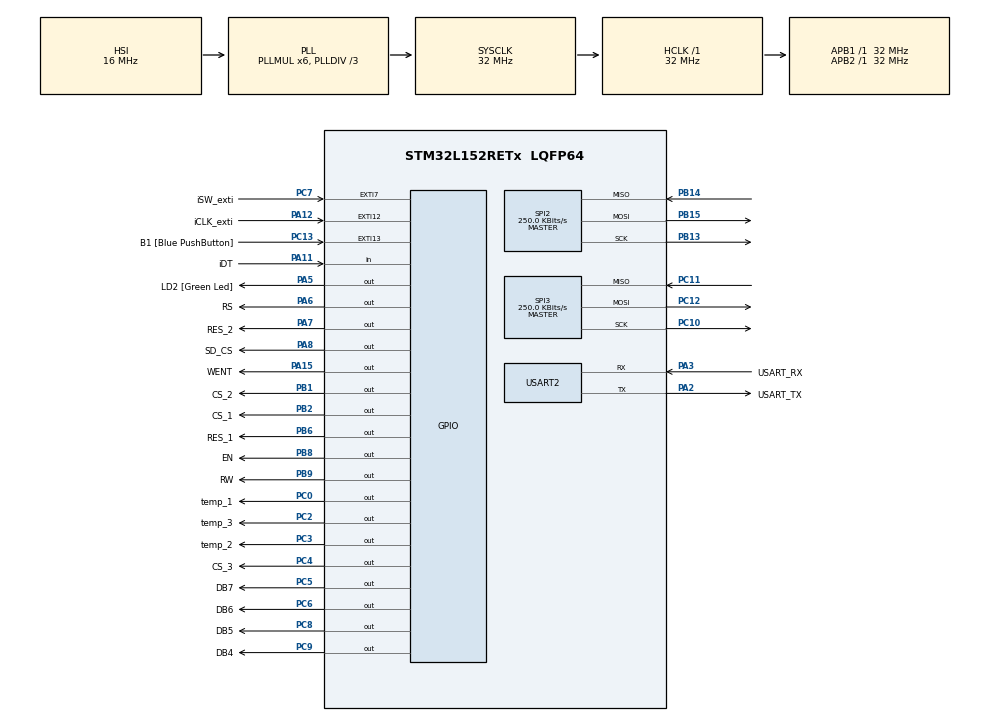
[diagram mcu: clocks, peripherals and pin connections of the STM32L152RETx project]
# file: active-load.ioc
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FATFS._FS_TIMEOUT=100000
Mcu.Family=STM32L1
Mcu.Name=STM32L152RETx
Mcu.Package=LQFP64
NVIC.EXTI15_10_IRQn=true\:0\:0\:false\:false\:true\:true\:true\:true
NVIC.EXTI9_5_IRQn=true\:0\:0\:false\:false\:true\:true\:true\:true
NVIC.PriorityGroup=NVIC_PRIORITYGROUP_0
NVIC.SPI3_IRQn=true\:0\:0\:false\:false\:true\:true\:true\:true
NVIC.TIM2_IRQn=true\:0\:0\:false\:false\:true\:true\:true\:true
NVIC.USART2_IRQn=true\:0\:0\:false\:false\:true\:true\:true\:true
PA11.GPIO_Label=iDT
PA11.GPIO_PuPd=GPIO_PULLDOWN
PA11.Signal=GPIO_Input
PA12.GPIO_Label=iCLK_exti
PA12.GPIO_ModeDefaultEXTI=GPIO_MODE_IT_FALLING
PA12.GPIO_PuPd=GPIO_PULLDOWN
PA12.Signal=GPXTI12
PA13.GPIO_Label=TMS
PA13.Mode=Serial_Wire
PA13.Signal=SYS_JTMS-SWDIO
PA14.GPIO_Label=TCK
PA14.Mode=Serial_Wire
PA14.Signal=SYS_JTCK-SWCLK
PA15.GPIO_Label=WENT
PA15.PinState=GPIO_PIN_SET
PA15.Signal=GPIO_Output
PA2.GPIO_Label=USART_TX
PA2.Mode=Asynchronous
PA2.Signal=USART2_TX
PA3.GPIO_Label=USART_RX
PA3.Mode=Asynchronous
PA3.Signal=USART2_RX
PA5.GPIO_Label=LD2 [Green Led]
PA5.Signal=GPIO_Output
PA6.GPIO_Label=RS
PA6.Signal=GPIO_Output
PA7.GPIO_Label=RES_2
PA7.Signal=GPIO_Output
PA8.GPIO_Label=SD_CS
PA8.GPIO_PuPd=GPIO_NOPULL
PA8.GPIO_Speed=GPIO_SPEED_FREQ_MEDIUM
PA8.PinState=GPIO_PIN_SET
PA8.Signal=GPIO_Output
PB1.GPIO_Label=CS_2
PB1.GPIO_PuPd=GPIO_PULLUP
PB1.GPIO_Speed=GPIO_SPEED_FREQ_MEDIUM
PB1.PinState=GPIO_PIN_SET
PB1.Signal=GPIO_Output
PB13.GPIO_PuPd=GPIO_NOPULL
PB13.GPIO_Speed=GPIO_SPEED_FREQ_MEDIUM
PB13.Mode=Full_Duplex_Master
PB13.Signal=SPI2_SCK
PB14.GPIO_PuPd=GPIO_PULLDOWN
PB14.GPIO_Speed=GPIO_SPEED_FREQ_MEDIUM
PB14.Mode=Full_Duplex_Master
PB14.Signal=SPI2_MISO
PB15.GPIO_PuPd=GPIO_NOPULL
PB15.GPIO_Speed=GPIO_SPEED_FREQ_MEDIUM
PB15.Mode=Full_Duplex_Master
PB15.Signal=SPI2_MOSI
PB2.GPIO_Label=CS_1
PB2.GPIO_PuPd=GPIO_PULLUP
PB2.GPIO_Speed=GPIO_SPEED_FREQ_MEDIUM
PB2.PinState=GPIO_PIN_SET
PB2.Signal=GPIO_Output
PB3.GPIO_Label=SWO
PB3.Signal=SYS_JTDO-TRACESWO
PB6.GPIO_Label=RES_1
PB6.Signal=GPIO_Output
PB8.GPIO_Label=EN
PB8.GPIO_PuPd=GPIO_NOPULL
PB8.Signal=GPIO_Output
PB9.GPIO_Label=RW
PB9.Signal=GPIO_Output
PC0.GPIO_Label=temp_1
PC0.GPIO_ModeDefaultOutputPP=GPIO_MODE_OUTPUT_OD
PC0.GPIO_PuPd=GPIO_NOPULL
PC0.GPIO_Speed=GPIO_SPEED_FREQ_MEDIUM
PC0.PinState=GPIO_PIN_RESET
PC0.Signal=GPIO_Output
PC10.GPIO_Speed=GPIO_SPEED_FREQ_MEDIUM
PC10.Mode=Full_Duplex_Master
PC10.Signal=SPI3_SCK
PC11.GPIO_PuPd=GPIO_PULLUP
PC11.GPIO_Speed=GPIO_SPEED_FREQ_MEDIUM
PC11.Mode=Full_Duplex_Master
PC11.Signal=SPI3_MISO
PC12.GPIO_Speed=GPIO_SPEED_FREQ_MEDIUM
PC12.Mode=Full_Duplex_Master
PC12.Signal=SPI3_MOSI
PC13-WKUP2.GPIO_Label=B1 [Blue PushButton]
PC13-WKUP2.GPIO_ModeDefaultEXTI=GPIO_MODE_IT_FALLING
PC13-WKUP2.Signal=GPXTI13
PC14-OSC32_IN.Mode=LSE-External-Oscillator
PC14-OSC32_IN.Signal=RCC_OSC32_IN
PC15-OSC32_OUT.Mode=LSE-External-Oscillator
PC15-OSC32_OUT.Signal=RCC_OSC32_OUT
PC2.GPIO_Label=temp_3
PC2.GPIO_ModeDefaultOutputPP=GPIO_MODE_OUTPUT_OD
PC2.GPIO_PuPd=GPIO_NOPULL
PC2.GPIO_Speed=GPIO_SPEED_FREQ_MEDIUM
PC2.Signal=GPIO_Output
PC3.GPIO_Label=temp_2
PC3.GPIO_ModeDefaultOutputPP=GPIO_MODE_OUTPUT_OD
PC3.GPIO_PuPd=GPIO_NOPULL
PC3.GPIO_Speed=GPIO_SPEED_FREQ_MEDIUM
PC3.Signal=GPIO_Output
PC4.GPIO_Label=CS_3
PC4.GPIO_PuPd=GPIO_PULLUP
PC4.GPIO_Speed=GPIO_SPEED_FREQ_MEDIUM
PC4.PinState=GPIO_PIN_SET
PC4.Signal=GPIO_Output
PC5.GPIO_Label=DB7
PC5.Signal=GPIO_Output
PC6.GPIO_Label=DB6
PC6.Signal=GPIO_Output
PC7.GPIO_Label=iSW_exti
PC7.GPIO_ModeDefaultEXTI=GPIO_MODE_IT_FALLING
PC7.GPIO_PuPd=GPIO_PULLUP
PC7.Signal=GPXTI7
PC8.GPIO_Label=DB5
PC8.Signal=GPIO_Output
PC9.GPIO_Label=DB4
PC9.Signal=GPIO_Output
PH0-OSC_IN.Mode=HSE-External-Clock-Source
PH0-OSC_IN.Signal=RCC_OSC_IN
PH1-OSC_OUT.Signal=RCC_OSC_OUT
ProjectManager.HeapSize=0x200
ProjectManager.StackSize=0x400
ProjectManager.TargetToolchain=CMake
RCC.48MHZClocksFreq_Value=48000000
RCC.AHBFreq_Value=32000000
RCC.APB1Freq_Value=32000000
RCC.APB1TimFreq_Value=32000000
RCC.APB2Freq_Value=32000000
RCC.APB2TimFreq_Value=32000000
RCC.HCLKFreq_Value=32000000
RCC.HSE_VALUE=8000000
RCC.HSI_VALUE=16000000
RCC.MSI_VALUE=2097000
RCC.PLLDIV=RCC_PLL_DIV3
RCC.PLLMUL=RCC_PLL_MUL6
RCC.RTCClockSelectionVirtual=RCC_RTCCLKSOURCE_LSE
RCC.SYSCLKFreq_VALUE=32000000
RCC.SYSCLKSource=RCC_SYSCLKSOURCE_PLLCLK
RCC.USBOutput=48000000
RCC.VCOOutputFreq_Value=96000000
RTC.Date=26
RTC.Format=RTC_FORMAT_BIN
RTC.Hours=8
RTC.Minutes=16
RTC.Month=RTC_MONTH_APRIL
RTC.Seconds=30
RTC.WakeUpClock-WakeUp=RTC_WAKEUPCLOCK_CK_SPRE_16BITS
RTC.WeekDay=RTC_WEEKDAY_SATURDAY
RTC.Year=25
SPI2.BaudRatePrescaler=SPI_BAUDRATEPRESCALER_128
SPI2.CLKPolarity=SPI_POLARITY_LOW
SPI2.CalculateBaudRate=250.0 KBits/s
SPI2.Direction=SPI_DIRECTION_2LINES
SPI2.Mode=SPI_MODE_MASTER
SPI2.VirtualType=VM_MASTER
SPI3.BaudRatePrescaler=SPI_BAUDRATEPRESCALER_128
SPI3.CalculateBaudRate=250.0 KBits/s
SPI3.Direction=SPI_DIRECTION_2LINES
SPI3.Mode=SPI_MODE_MASTER
SPI3.VirtualType=VM_MASTER
TIM2.Period=99
TIM2.Prescaler=15999
TIM6.Prescaler=31
USART2.VirtualMode=VM_ASYNC
VP_FATFS_VS_Generic.Mode=User_defined
VP_RTC_VS_RTC_Activate.Mode=RTC_Enabled
VP_RTC_VS_RTC_WakeUp_intern.Mode=WakeUp
VP_TIM2_VS_ClockSourceINT.Mode=Internal
VP_TIM6_VS_ClockSourceINT.Mode=Enable_Timer
board=NUCLEO-L152RE

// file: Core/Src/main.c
/* USER CODE BEGIN Header */
/**
  ******************************************************************************
  * @file           : main.c
  * @brief          : Main program body
  ******************************************************************************
  * @attention
  *
  * Copyright (c) 2026 STMicroelectronics.
  * All rights reserved.
  *
  * This software is licensed under terms that can be found in the LICENSE file
  * in the root directory of this software component.
  * If no LICENSE file comes with this software, it is provided AS-IS.
  *
  ******************************************************************************
  */
/* USER CODE END Header */
#include "main.h"
#include "fatfs.h"
#include "rtc.h"
#include "spi.h"
#include "tim.h"
#include "usart.h"
#include "gpio.h"

/* USER CODE BEGIN Includes */
#include "app.h"
#include "comms.h"

/* USER CODE END Includes */

void SystemClock_Config(void);

int main(void)
{

  /* MCU Configuration--------------------------------------------------------*/

  /* Reset of all peripherals, Initializes the Flash interface and the Systick. */
  HAL_Init();

  /* Configure the system clock */
  SystemClock_Config();

  /* Initialize all configured peripherals */
  MX_GPIO_Init();
  MX_USART2_UART_Init();
  MX_RTC_Init();
  MX_TIM2_Init();
  MX_FATFS_Init();
  MX_SPI2_Init();
  MX_TIM6_Init();
  MX_SPI3_Init();
  /* USER CODE BEGIN 2 */
  if ( app_Init() != APP_INIT_DONE )
  {
    Error_Handler();
  }

  if ( HAL_TIM_Base_Start_IT(&htim2) != HAL_OK )
  {
    Error_Handler();
  }

  if ( HAL_TIM_Base_Start(&htim6) != HAL_OK )
  {
    Error_Handler();
  }

  if ( COMMS_StartRx(&huart2) != HAL_OK )
  {
    Error_Handler();
  }

  /* USER CODE END 2 */

  /* Infinite loop */
  while (1)
  {

    /* USER CODE BEGIN 3 */
    app_Process();
  }
  /* USER CODE END 3 */
}

void SystemClock_Config(void)
{
  RCC_OscInitTypeDef RCC_OscInitStruct = {0};
  RCC_ClkInitTypeDef RCC_ClkInitStruct = {0};
  RCC_PeriphCLKInitTypeDef PeriphClkInit = {0};

  /** Configure the main internal regulator output voltage
  */
  __HAL_PWR_VOLTAGESCALING_CONFIG(PWR_REGULATOR_VOLTAGE_SCALE1);

  /** Initializes the RCC Oscillators according to the specified parameters
  * in the RCC_OscInitTypeDef structure.
  */
  RCC_OscInitStruct.OscillatorType = RCC_OSCILLATORTYPE_HSI|RCC_OSCILLATORTYPE_LSE;
  RCC_OscInitStruct.LSEState = RCC_LSE_ON;
  RCC_OscInitStruct.HSIState = RCC_HSI_ON;
  RCC_OscInitStruct.HSICalibrationValue = RCC_HSICALIBRATION_DEFAULT;
  RCC_OscInitStruct.PLL.PLLState = RCC_PLL_ON;
  RCC_OscInitStruct.PLL.PLLSource = RCC_PLLSOURCE_HSI;
  RCC_OscInitStruct.PLL.PLLMUL = RCC_PLL_MUL6;
  RCC_OscInitStruct.PLL.PLLDIV = RCC_PLL_DIV3;
  if (HAL_RCC_OscConfig(&RCC_OscInitStruct) != HAL_OK)
  {
    Error_Handler();
  }

  /** Initializes the CPU, AHB and APB buses clocks
  */
  RCC_ClkInitStruct.ClockType = RCC_CLOCKTYPE_HCLK|RCC_CLOCKTYPE_SYSCLK
                              |RCC_CLOCKTYPE_PCLK1|RCC_CLOCKTYPE_PCLK2;
  RCC_ClkInitStruct.SYSCLKSource = RCC_SYSCLKSOURCE_PLLCLK;
  RCC_ClkInitStruct.AHBCLKDivider = RCC_SYSCLK_DIV1;
  RCC_ClkInitStruct.APB1CLKDivider = RCC_HCLK_DIV1;
  RCC_ClkInitStruct.APB2CLKDivider = RCC_HCLK_DIV1;

  if (HAL_RCC_ClockConfig(&RCC_ClkInitStruct, FLASH_LATENCY_1) != HAL_OK)
  {
    Error_Handler();
  }
  PeriphClkInit.PeriphClockSelection = RCC_PERIPHCLK_RTC;
  PeriphClkInit.RTCClockSelection = RCC_RTCCLKSOURCE_LSE;
  if (HAL_RCCEx_PeriphCLKConfig(&PeriphClkInit) != HAL_OK)
  {
    Error_Handler();
  }
}

/* USER CODE BEGIN 4 */
void HAL_TIM_PeriodElapsedCallback(TIM_HandleTypeDef *htim)
{
  if ( htim->Instance == TIM2 )
  {
    app_Notify50msFromIsr();
  }
}

/* USER CODE END 4 */

void Error_Handler(void)
{
  __disable_irq();
  while (1)
  {
  }
}
